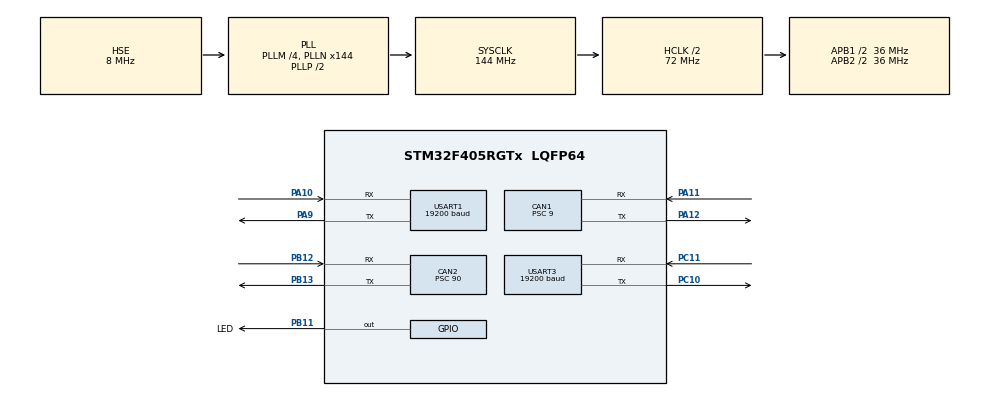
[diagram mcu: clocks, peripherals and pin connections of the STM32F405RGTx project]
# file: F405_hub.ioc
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CAN1.BS1=CAN_BS1_13TQ
CAN1.BS2=CAN_BS2_2TQ
CAN1.CalculateBaudRate=250000
CAN1.CalculateTimeBit=4000.00
CAN1.CalculateTimeQuantum=250.0
CAN1.Prescaler=9
CAN2.BS1=CAN_BS1_13TQ
CAN2.BS2=CAN_BS2_2TQ
CAN2.CalculateBaudRate=25000
CAN2.CalculateTimeBit=40000.00
CAN2.CalculateTimeQuantum=2500.0
CAN2.Prescaler=90
Mcu.Family=STM32F4
Mcu.Name=STM32F405RGTx
Mcu.Package=LQFP64
NVIC.PriorityGroup=NVIC_PRIORITYGROUP_4
PA10.Mode=Asynchronous
PA10.Signal=USART1_RX
PA11.Mode=CAN_Activate
PA11.Signal=CAN1_RX
PA12.Mode=CAN_Activate
PA12.Signal=CAN1_TX
PA9.Mode=Asynchronous
PA9.Signal=USART1_TX
PB11.GPIO_Label=LED
PB11.Signal=GPIO_Output
PB12.Mode=CAN_Activate
PB12.Signal=CAN2_RX
PB13.Mode=CAN_Activate
PB13.Signal=CAN2_TX
PC10.Mode=Asynchronous
PC10.Signal=USART3_TX
PC11.Mode=Asynchronous
PC11.Signal=USART3_RX
PH0-OSC_IN.Mode=HSE-External-Oscillator
PH0-OSC_IN.Signal=RCC_OSC_IN
PH1-OSC_OUT.Mode=HSE-External-Oscillator
PH1-OSC_OUT.Signal=RCC_OSC_OUT
ProjectManager.HeapSize=0x2000
ProjectManager.StackSize=0x4000
ProjectManager.TargetToolchain=STM32CubeIDE
RCC.48MHZClocksFreq_Value=41142857.14285714
RCC.AHBCLKDivider=RCC_SYSCLK_DIV2
RCC.AHBFreq_Value=72000000
RCC.APB1CLKDivider=RCC_HCLK_DIV2
RCC.APB1Freq_Value=36000000
RCC.APB1TimFreq_Value=72000000
RCC.APB2CLKDivider=RCC_HCLK_DIV2
RCC.APB2Freq_Value=36000000
RCC.APB2TimFreq_Value=72000000
RCC.CortexFreq_Value=72000000
RCC.HCLKFreq_Value=72000000
RCC.HSE_VALUE=8000000
RCC.HSI_VALUE=16000000
RCC.LSE_VALUE=32768
RCC.PLLI2SR=4
RCC.PLLM=4
RCC.PLLN=144
RCC.PLLQ=7
RCC.PLLSourceVirtual=RCC_PLLSOURCE_HSE
RCC.SYSCLKFreq_VALUE=144000000
RCC.SYSCLKSource=RCC_SYSCLKSOURCE_PLLCLK
RCC.VCOOutputFreq_Value=288000000
USART1.BaudRate=19200
USART1.VirtualMode=VM_ASYNC
USART3.BaudRate=19200
USART3.VirtualMode=VM_ASYNC
board=custom

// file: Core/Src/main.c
/* USER CODE BEGIN Header */
/**
  ******************************************************************************
  * @file           : main.c
  * @brief          : Main program body
  ******************************************************************************
  * @attention
  *
  * <h2><center>&copy; Copyright (c) 2021 STMicroelectronics.
  * All rights reserved.</center></h2>
  *
  * This software component is licensed by ST under BSD 3-Clause license,
  * the "License"; You may not use this file except in compliance with the
  * License. You may obtain a copy of the License at:
  *                        opensource.org/licenses/BSD-3-Clause
  *
  ******************************************************************************
  */
/* USER CODE END Header */
#include "main.h"

CAN_HandleTypeDef hcan1;
CAN_HandleTypeDef hcan2;

UART_HandleTypeDef huart1;
UART_HandleTypeDef huart3;

/* USER CODE BEGIN PV */
char message_tx [30];
/* USER CODE END PV */

void SystemClock_Config(void);
static void MX_GPIO_Init(void);
static void MX_CAN1_Init(void);
static void MX_CAN2_Init(void);
static void MX_USART1_UART_Init(void);
static void MX_USART3_UART_Init(void);

int main(void)
{

  /* MCU Configuration--------------------------------------------------------*/

  /* Reset of all peripherals, Initializes the Flash interface and the Systick. */
  HAL_Init();

  /* Configure the system clock */
  SystemClock_Config();

  /* Initialize all configured peripherals */
  MX_GPIO_Init();
  MX_CAN1_Init();
  MX_CAN2_Init();
  MX_USART1_UART_Init();
  MX_USART3_UART_Init();

  /* Infinite loop */
  while (1)
  {

    /* USER CODE BEGIN 3 */
	HAL_GPIO_TogglePin (LED_GPIO_Port, LED_Pin);
	if (HAL_GPIO_ReadPin (LED_GPIO_Port, LED_Pin))
		sprintf (message_tx, "led_on\r\n");
	else
		sprintf (message_tx, "led_off\r\n");
	HAL_UART_Transmit (&huart1, (unsigned char*)message_tx, 8, 0xFFFF);
	HAL_Delay (PERIOD);
  }
  /* USER CODE END 3 */
}

void SystemClock_Config(void)
{
  RCC_OscInitTypeDef RCC_OscInitStruct = {0};
  RCC_ClkInitTypeDef RCC_ClkInitStruct = {0};

  /** Configure the main internal regulator output voltage
  */
  __HAL_RCC_PWR_CLK_ENABLE();
  __HAL_PWR_VOLTAGESCALING_CONFIG(PWR_REGULATOR_VOLTAGE_SCALE1);
  /** Initializes the RCC Oscillators according to the specified parameters
  * in the RCC_OscInitTypeDef structure.
  */
  RCC_OscInitStruct.OscillatorType = RCC_OSCILLATORTYPE_HSE;
  RCC_OscInitStruct.HSEState = RCC_HSE_ON;
  RCC_OscInitStruct.PLL.PLLState = RCC_PLL_ON;
  RCC_OscInitStruct.PLL.PLLSource = RCC_PLLSOURCE_HSE;
  RCC_OscInitStruct.PLL.PLLM = 4;
  RCC_OscInitStruct.PLL.PLLN = 144;
  RCC_OscInitStruct.PLL.PLLP = RCC_PLLP_DIV2;
  RCC_OscInitStruct.PLL.PLLQ = 7;
  if (HAL_RCC_OscConfig(&RCC_OscInitStruct) != HAL_OK)
  {
    Error_Handler();
  }
  /** Initializes the CPU, AHB and APB buses clocks
  */
  RCC_ClkInitStruct.ClockType = RCC_CLOCKTYPE_HCLK|RCC_CLOCKTYPE_SYSCLK
                              |RCC_CLOCKTYPE_PCLK1|RCC_CLOCKTYPE_PCLK2;
  RCC_ClkInitStruct.SYSCLKSource = RCC_SYSCLKSOURCE_PLLCLK;
  RCC_ClkInitStruct.AHBCLKDivider = RCC_SYSCLK_DIV2;
  RCC_ClkInitStruct.APB1CLKDivider = RCC_HCLK_DIV2;
  RCC_ClkInitStruct.APB2CLKDivider = RCC_HCLK_DIV2;

  if (HAL_RCC_ClockConfig(&RCC_ClkInitStruct, FLASH_LATENCY_2) != HAL_OK)
  {
    Error_Handler();
  }
}

static void MX_CAN1_Init(void)
{

  hcan1.Instance = CAN1;
  hcan1.Init.Prescaler = 9;
  hcan1.Init.Mode = CAN_MODE_NORMAL;
  hcan1.Init.SyncJumpWidth = CAN_SJW_1TQ;
  hcan1.Init.TimeSeg1 = CAN_BS1_13TQ;
  hcan1.Init.TimeSeg2 = CAN_BS2_2TQ;
  hcan1.Init.TimeTriggeredMode = DISABLE;
  hcan1.Init.AutoBusOff = DISABLE;
  hcan1.Init.AutoWakeUp = DISABLE;
  hcan1.Init.AutoRetransmission = DISABLE;
  hcan1.Init.ReceiveFifoLocked = DISABLE;
  hcan1.Init.TransmitFifoPriority = DISABLE;
  if (HAL_CAN_Init(&hcan1) != HAL_OK)
  {
    Error_Handler();
  }

}

static void MX_CAN2_Init(void)
{

  hcan2.Instance = CAN2;
  hcan2.Init.Prescaler = 90;
  hcan2.Init.Mode = CAN_MODE_NORMAL;
  hcan2.Init.SyncJumpWidth = CAN_SJW_1TQ;
  hcan2.Init.TimeSeg1 = CAN_BS1_13TQ;
  hcan2.Init.TimeSeg2 = CAN_BS2_2TQ;
  hcan2.Init.TimeTriggeredMode = DISABLE;
  hcan2.Init.AutoBusOff = DISABLE;
  hcan2.Init.AutoWakeUp = DISABLE;
  hcan2.Init.AutoRetransmission = DISABLE;
  hcan2.Init.ReceiveFifoLocked = DISABLE;
  hcan2.Init.TransmitFifoPriority = DISABLE;
  if (HAL_CAN_Init(&hcan2) != HAL_OK)
  {
    Error_Handler();
  }

}

static void MX_USART1_UART_Init(void)
{

  huart1.Instance = USART1;
  huart1.Init.BaudRate = 19200;
  huart1.Init.WordLength = UART_WORDLENGTH_8B;
  huart1.Init.StopBits = UART_STOPBITS_1;
  huart1.Init.Parity = UART_PARITY_NONE;
  huart1.Init.Mode = UART_MODE_TX_RX;
  huart1.Init.HwFlowCtl = UART_HWCONTROL_NONE;
  huart1.Init.OverSampling = UART_OVERSAMPLING_16;
  if (HAL_UART_Init(&huart1) != HAL_OK)
  {
    Error_Handler();
  }

}

static void MX_USART3_UART_Init(void)
{

  huart3.Instance = USART3;
  huart3.Init.BaudRate = 19200;
  huart3.Init.WordLength = UART_WORDLENGTH_8B;
  huart3.Init.StopBits = UART_STOPBITS_1;
  huart3.Init.Parity = UART_PARITY_NONE;
  huart3.Init.Mode = UART_MODE_TX_RX;
  huart3.Init.HwFlowCtl = UART_HWCONTROL_NONE;
  huart3.Init.OverSampling = UART_OVERSAMPLING_16;
  if (HAL_UART_Init(&huart3) != HAL_OK)
  {
    Error_Handler();
  }

}

static void MX_GPIO_Init(void)
{
  GPIO_InitTypeDef GPIO_InitStruct = {0};

  /* GPIO Ports Clock Enable */
  __HAL_RCC_GPIOH_CLK_ENABLE();
  __HAL_RCC_GPIOB_CLK_ENABLE();
  __HAL_RCC_GPIOA_CLK_ENABLE();
  __HAL_RCC_GPIOC_CLK_ENABLE();

  /*Configure GPIO pin Output Level */
  HAL_GPIO_WritePin(LED_GPIO_Port, LED_Pin, GPIO_PIN_RESET);

  /*Configure GPIO pin : LED_Pin */
  GPIO_InitStruct.Pin = LED_Pin;
  GPIO_InitStruct.Mode = GPIO_MODE_OUTPUT_PP;
  GPIO_InitStruct.Pull = GPIO_NOPULL;
  GPIO_InitStruct.Speed = GPIO_SPEED_FREQ_LOW;
  HAL_GPIO_Init(LED_GPIO_Port, &GPIO_InitStruct);

}

void Error_Handler(void)
{
  __disable_irq();
  while (1)
  {
  }
}

/************************ (C) COPYRIGHT STMicroelectronics *****END OF FILE****/
